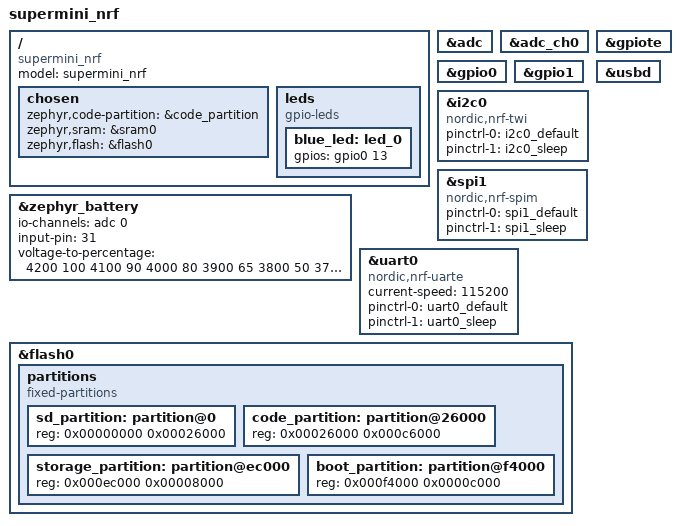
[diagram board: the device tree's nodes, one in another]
/*
 * Copyright (c) 2021 The ZMK Contributors
 *
 * SPDX-License-Identifier: MIT
 */

#include <nordic/nrf52840_qiaa.dtsi>
#include "supermini_nrf-pinctrl.dtsi"
#include "arduino_pro_micro_pins.dtsi"

/ {
    model = "supermini_nrf";
    compatible = "supermini_nrf";

    chosen {
        zephyr,code-partition = &code_partition;
        zephyr,sram = &sram0;
        zephyr,flash = &flash0;
    };

    leds {
        compatible = "gpio-leds";
        blue_led: led_0 {
            gpios = <&gpio0 13 GPIO_ACTIVE_HIGH>;
        };
    };
};

&adc {
    status = "okay";
    // battery_voltage: battery_voltage {
    //     io-channels = <&adc 0>; /* Assuming you use ADC channel 0 */
    //     input-positive = <NRF_SAADC_INPUT_AIN0>;
    //     /* if voltage divider exists: define ratio */
    //     zephyr,voltage-divider = <100 100>; /* example 2:1 divider */
    // };
};
&adc_ch0{
    status = "okay";
};
&zephyr_battery {
    io-channels = <&adc 0>; /* ADC channel 0 */
    input-pin = <31>; /* P0.31 */
    voltage-to-percentage = <
        4200 100
        4100 90
        4000 80
        3900 65
        3800 50
        3700 30
        3600 10
        3500 0
    >;
};

&gpiote {
    status = "okay";
};

&gpio0 {
    status = "okay";
};

&gpio1 {
    status = "okay";
};

&i2c0 {
    compatible = "nordic,nrf-twi";
    pinctrl-0 = <&i2c0_default>;
    pinctrl-1 = <&i2c0_sleep>;
    pinctrl-names = "default", "sleep";
};

&spi1 {
    compatible = "nordic,nrf-spim";
    pinctrl-0 = <&spi1_default>;
    pinctrl-1 = <&spi1_sleep>;
    pinctrl-names = "default", "sleep";
};

&uart0 {
    compatible = "nordic,nrf-uarte";
    current-speed = <115200>;
    pinctrl-0 = <&uart0_default>;
    pinctrl-1 = <&uart0_sleep>;
    pinctrl-names = "default", "sleep";
};

zephyr_udc0: &usbd {
    status = "okay";
};

&flash0 {
    /*
     * For more information, see:
     * http://docs.zephyrproject.org/latest/devices/dts/flash_partitions.html
     */
    partitions {
        compatible = "fixed-partitions";
        #address-cells = <1>;
        #size-cells = <1>;

        sd_partition: partition@0 {
            reg = <0x00000000 0x00026000>;
        };
        code_partition: partition@26000 {
            reg = <0x00026000 0x000c6000>;
        };

        /*
         * The flash starting at 0x000ec000 and ending at
         * 0x000f3fff is reserved for use by the application.
         */

        /*
         * Storage partition will be used by FCB/LittleFS/NVS
         * if enabled.
         */
        storage_partition: partition@ec000 {
            reg = <0x000ec000 0x00008000>;
        };

        boot_partition: partition@f4000 {
            reg = <0x000f4000 0x0000c000>;
        };
    };
};
